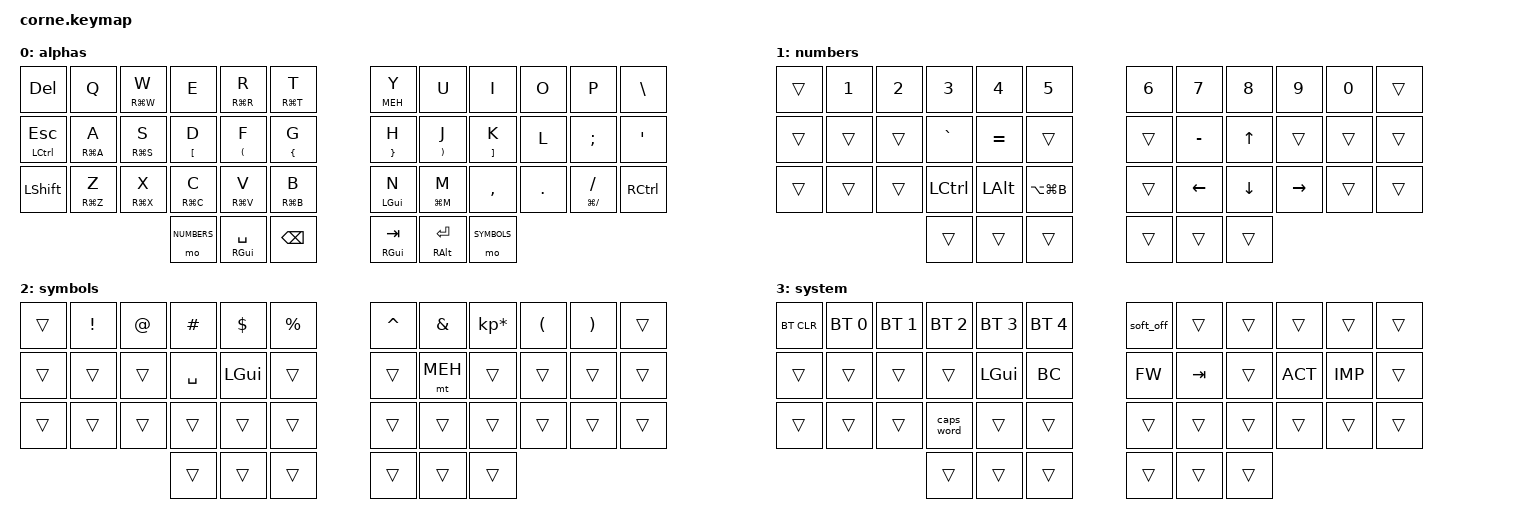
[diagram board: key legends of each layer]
#include <behaviors.dtsi>
#include <dt-bindings/zmk/keys.h>
#include <dt-bindings/zmk/bt.h>

#define BASE 0 // default_layer index
#define NUMBERS 1 // lower_layer index
#define SYMBOLS 2 // raise_layer index
#define SYSTEM 3 // tri_layer index

// Meh = Ctrl + Shift + Alt
#define MEH LA(LC(LSHIFT))
// Import = Alt + Shift + Enter
#define IMP LA(LS(ENTER))
// Action = Alt + Enter
#define ACT LA(ENTER)
// Back = Alt + Command + <-
#define BC LA(LG(LEFT))
// Forward = Alt + Command + ->
#define FW LA(LG(RIGHT))


&caps_word {
    // when using caps word, allow for undescore and minus as they are commonly used for constants in programming languages
    continue-list = <DELETE BACKSPACE UNDERSCORE LEFT RIGHT LCTRL RCTRL LGUI RGUI>;
};

&mt {
    // sane defaults
    tapping-term-ms = <250>;
    flavor = "tap-preferred";
};

&soft_off {
    hold-time-ms = <100>;
};

// Key index reference:

// 00 01 02 03 04 05 | 06 07 08 09 10 11
// 12 13 14 15 16 17 | 18 19 20 21 22 23
// 24 25 26 27 28 29 | 30 31 32 33 34 35
//          36 37 38 | 39 40 41

#define LEFT_MOD 36 // left thumb layer modifier key index
#define RIGHT_MOD 41 // right thumb layer modifier key index

/ {
    conditional_layers {
        compatible = "zmk,conditional-layers";
        tri_layer {
            // Switch to system layer if both layer switch keys are pressed at the same time
            if-layers = <NUMBERS SYMBOLS>;
            then-layer = <SYSTEM>;
        };
    };

    keymap {
        compatible = "zmk,keymap";

        default_layer {
            label = "alphas";
            bindings = <
                &kp DEL       &kp Q       &mt RG(W) W &kp E       &mt RG(R) R &mt RG(T) T      &mt MEH Y     &kp U     &kp I      &kp O   &kp P         &kp BSLH
                &mt LCTRL ESC &mt RG(A) A &mt RG(S) S &mt LBKT D  &mt LPAR F  &mt LBRC G       &mt RBRC H    &mt RPAR J    &mt RBKT K &kp L   &kp SEMI      &kp SQT
                &kp LSHFT     &mt RG(Z) Z &mt RG(X) X &mt RG(C) C &mt RG(V) V &mt RG(B) B      &mt LGUI N    &mt LG(M) M   &kp COMMA  &kp DOT &mt LG(FSLH) FSLH &kp RCTRL
                                      &mo NUMBERS &mt RGUI SPACE  &kp BSPC     &mt RGUI TAB  &mt RALT RET  &mo SYMBOLS
            >;
        };

        lower_layer {
            label = "numbers";
            bindings = <
                &trans &kp N1 &kp N2 &kp N3    &kp N4    &kp N5         &kp N6 &kp N7    &kp N8   &kp N9    &kp N0 &trans
                &trans &trans &trans &kp GRAVE &kp EQUAL &trans         &trans &kp MINUS &kp UP   &trans    &trans &trans
                &trans &trans &trans &kp LCTRL &kp LALT  &kp LA(LG(B))   &trans &kp LEFT  &kp DOWN &kp RIGHT &trans &trans
                             &trans    &trans    &trans         &trans &trans    &trans
            >;
        };

        raise_layer {
            label = "symbols";
            bindings = <
                &trans &kp EXCL &kp AT &kp HASH &kp DLLR &kp PRCNT      &kp CARET &kp AMPS  &kp KP_MULTIPLY &kp LPAR &kp RPAR &trans
                &trans &trans  &trans &kp SPACE &kp LGUI &trans     &trans    &mt MEH   &trans      &trans   &trans   &trans
                &trans &trans   &trans &trans   &trans   &trans     &trans    &trans    &trans      &trans   &trans   &trans
                               &trans   &trans   &trans     &trans    &trans    &trans
            >;
        };

        tri_layer {
            label = "system";
            bindings = <
                &bt BT_CLR &bt BT_SEL 0 &bt BT_SEL 1 &bt BT_SEL 2 &bt BT_SEL 3 &bt BT_SEL 4     &soft_off      &trans  &trans  &trans &trans  &trans
                &trans     &trans       &trans       &trans       &kp LGUI    &kp BC       &kp FW       &kp TAB &trans &kp ACT &kp IMP &trans
                &trans  &trans       &trans       &caps_word   &trans       &trans       &trans      &trans  &trans  &trans &trans  &trans
                                     &trans       &trans       &trans       &trans      &trans  &trans
            >;
        };
    };
};
